# M440 register map
File version: 0.1
Registers are 32-bit, read-write, reset 0x0 unless marked. A register's access mark holds for its fields unless they carry their own. Offsets are from the block's base; [hi:lo] are bit positions; {n}, {i} and the like mark numbered series.

## TC — 32-bit Timer (TC)
Base 0x440CE000
0x00 EN — TC Enable Register
  [7] TCEN
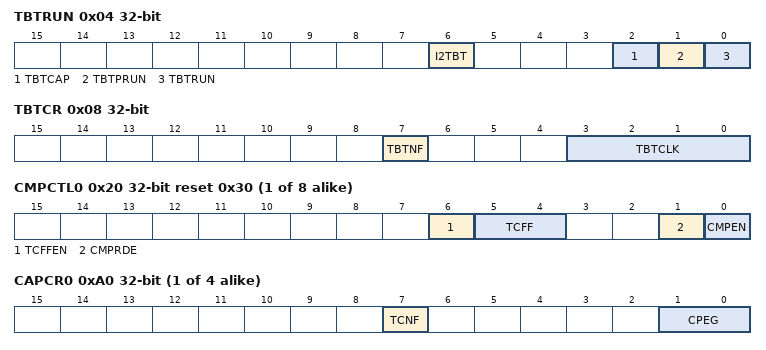
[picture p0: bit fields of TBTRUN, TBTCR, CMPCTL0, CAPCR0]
0x04 TBTRUN — TC RUN Register
  [6] I2TBT, [2] TBTCAP, [1] TBTPRUN, [0] TBTRUN
0x08 TBTCR — TC Control Register
  [7] TBTNF, [3:0] TBTCLK
0x0C TBTCP ro — TC TBT Capture Register
  [31:0] CAP
0x10 TBTRDCP ro — TC TBT Read Capture Register
  [31:0] RDCP
{0x20+0x10*i} CMPCTL{i} reset 0x30 (i=0..7) — TC Compare Control Register{i}
  [6] TCFFEN, [5:4] TCFF, [1] CMPRDE, [0] CMPEN
{0x24+0x10*i} CMP{i} (i=0..7) — TC Compare Register{i}
  [31:0] CMP
{0xA0+0x10*i} CAPCR{i} (i=0..3) — TC Capture Control Register{i}
  [7] TCNF, [1:0] CPEG
{0xA4+0x10*i} CAP{i} ro (i=0..3) — TC Capture Register{i}
  [31:0] CAP

## PHC0 — Two-phase Pulse Input Count
Base 0x400CA000
Same registers: PHC1 0x400CA100
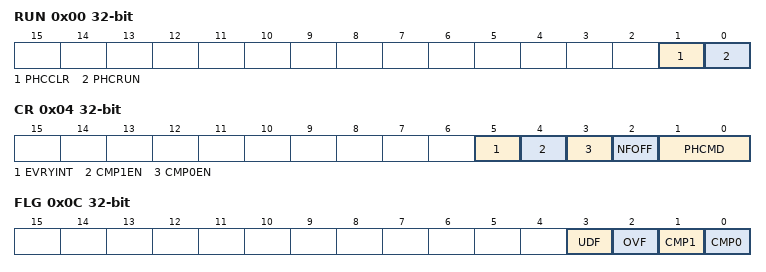
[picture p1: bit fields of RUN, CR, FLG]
0x00 RUN — Two-phase Pulse Input Count Run Register
  [1] PHCCLR, [0] PHCRUN
0x04 CR — Two-phase Pulse Input Count Control Register
  [5] EVRYINT, [4] CMP1EN, [3] CMP0EN, [2] NFOFF, [1:0] PHCMD
0x08 EN — Two-phase Pulse Input Count Timer Enable Register
  [0] PHCEN
0x0C FLG — Two-phase Pulse Input Count Status Register
  [3] UDF, [2] OVF, [1] CMP1, [0] CMP0
0x10 CMP0 — Two-phase Pulse Input Count Compare Register 0
  [15:0] PHCCMP0
0x14 CMP1 — Two-phase Pulse Input Count Compare Register 1
  [15:0] PHCCMP1
0x18 CNT ro reset 0x7FFF — Two-phase Pulse Input Count Counter Read Register
  [15:0] PHCCNT
0x1C DMA — Two-phase Pulse Input Count DMA Enable Register
  [2] PHCDMA2

## RTC — Real Time Clock (RTC)
Base 0x400CC000
0x00 SECR 8-bit (reset mask 0x80) — RTC Second Column Register
  [6:0] SE
0x01 MINR 8-bit (reset mask 0x80) — RTC Minute Column Register
  [6:0] MI
0x02 HOURR 8-bit (reset mask 0xC0) — RTC Hour Column Register
  [5:0] HO
0x04 DAYR 8-bit (reset mask 0xF8) — RTC Day of the Week Column Register
  [2:0] WE
0x05 DATER 8-bit (reset mask 0xC0) — RTC Day Column Register
  [5:0] DA
0x06 MONTHR_A 8-bit (reset mask 0xE0) — RTC Month Column Register
  [4:0] MO
0x06 MONTHR_B 8-bit (reset mask 0xFE) (RTC_MONTHR view) — RTC Month Column Register
  [0] MO0
0x07 YEARR_A 8-bit reset not defined — RTC Year Column Register
  [7:0] YE
0x07 YEARR_B 8-bit (reset mask 0xFC) (RTC_YEARR view) — RTC Year Column Register
  [1:0] LEAP
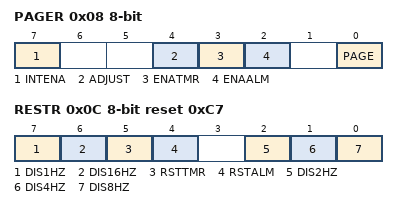
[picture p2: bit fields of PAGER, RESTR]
0x08 PAGER 8-bit (reset mask 0xF3) — RTC PAGE Register
  [7] INTENA, [4] ADJUST, [3] ENATMR, [2] ENAALM, [0] PAGE
0x0C RESTR 8-bit reset 0xC7 — RTC Reset Register
  [7] DIS1HZ, [6] DIS16HZ, [5] RSTTMR, [4] RSTALM, [2] DIS2HZ, [1] DIS4HZ, [0] DIS8HZ

## SBI — Serial Bus Interface (SBI)
Base 0x400E0000
0x00 CR0 — SBI Control Register 0
  [7] SBIEN
0x04 CR1_A reset 0x3 — SBI Control Register 1 (I2C Mode)
  [7:5] BC, [4] ACK, [0] SWRMON ro, [2:0] SCK wo
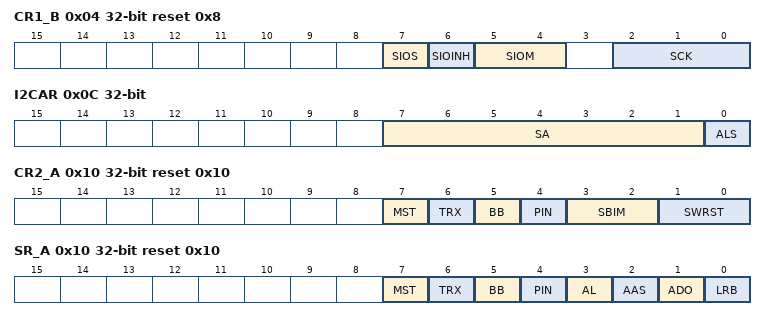
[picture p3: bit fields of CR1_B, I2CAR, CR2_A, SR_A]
0x04 CR1_B reset 0x8 (SBI_CR1 view) — SBI Control Register 1 (SIO Mode)
  [7] SIOS, [6] SIOINH, [5:4] SIOM, [2:0] SCK
0x08 DBR — SBI Data Buffer Register
  [7:0] DB
0x0C I2CAR — SBI I2C Bus Address Register
  [7:1] SA, [0] ALS
0x10 CR2_A wo reset 0x10 — SBI Control Register 2 (I2C Mode)
  [7] MST, [6] TRX, [5] BB, [4] PIN, [3:2] SBIM, [1:0] SWRST
0x10 CR2_B wo reset 0xF3 (SBI_CR2 view) — SBI Control Register 2 (SIO Mode)
  [3:2] SBIM
0x10 SR_A ro reset 0x10 — SBI Status Register (I2C Mode)
  [7] MST, [6] TRX, [5] BB, [4] PIN, [3] AL, [2] AAS, [1] ADO, [0] LRB
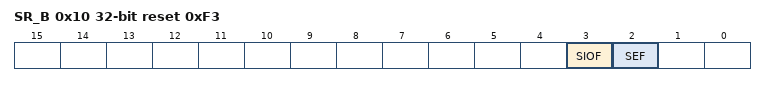
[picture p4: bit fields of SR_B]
0x10 SR_B ro reset 0xF3 (SBI_SR view) — SBI Status Register (SIO Mode)
  [3] SIOF, [2] SEF
0x14 BR0 reset 0xBE — SBI Baud Rate Register 0
  [6] I2SBI

## SC0 — Serial Channel (SC)
Base 0x440E1000
Same registers: SC1 0x440E1100, SC2 0x440E1200
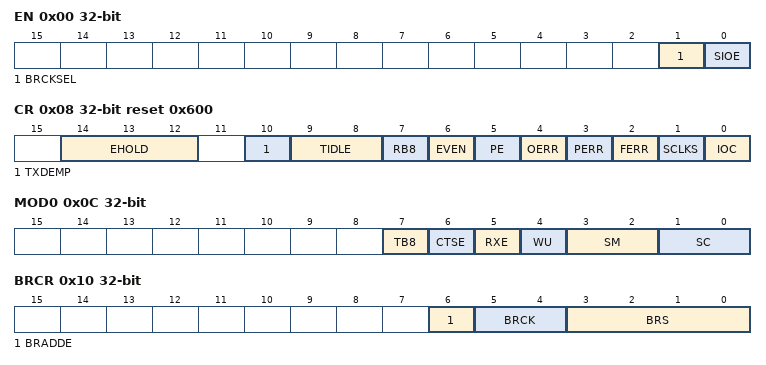
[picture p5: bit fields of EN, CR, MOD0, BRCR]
0x00 EN — SC Enable Register
  [1] BRCKSEL, [0] SIOE
0x04 BUF — SC Buffer Register
  [7:0] TB_RB
0x08 CR reset 0x600 — SC Control Register
  [14:12] EHOLD, [10] TXDEMP, [9:8] TIDLE, [7] RB8 ro, [6] EVEN, [5] PE, [4] OERR ro, [3] PERR ro, [2] FERR ro, [1] SCLKS, [0] IOC
0x0C MOD0 — SC Mode Control Register 0
  [7] TB8, [6] CTSE, [5] RXE, [4] WU, [3:2] SM, [1:0] SC
0x10 BRCR — SC Baud Rate Generator Control Register
  [6] BRADDE, [5:4] BRCK, [3:0] BRS
0x14 BRADD — SC Baud Rate Generator Control Register 2
  [3:0] BRK
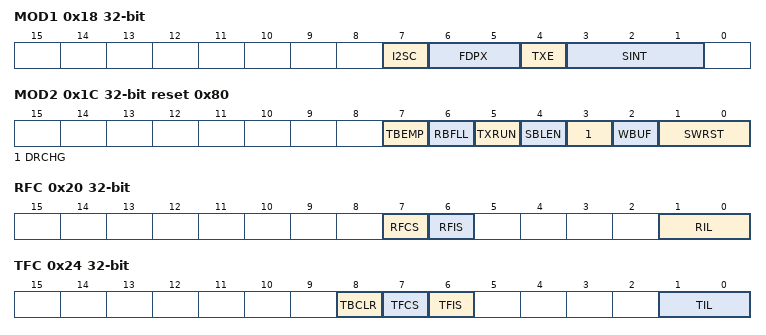
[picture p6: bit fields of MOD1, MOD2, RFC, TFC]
0x18 MOD1 — SC Mode Control Register 1
  [7] I2SC, [6:5] FDPX, [4] TXE, [3:1] SINT
0x1C MOD2 reset 0x80 — SC Mode Control Register 2
  [7] TBEMP ro, [6] RBFLL ro, [5] TXRUN ro, [4] SBLEN, [3] DRCHG, [2] WBUF, [1:0] SWRST
0x20 RFC — SC RX FIFO Configuration Register
  [7] RFCS wo, [6] RFIS, [1:0] RIL
0x24 TFC — SC TX FIFO Configuration Register
  [8] TBCLR, [7] TFCS, [6] TFIS, [1:0] TIL
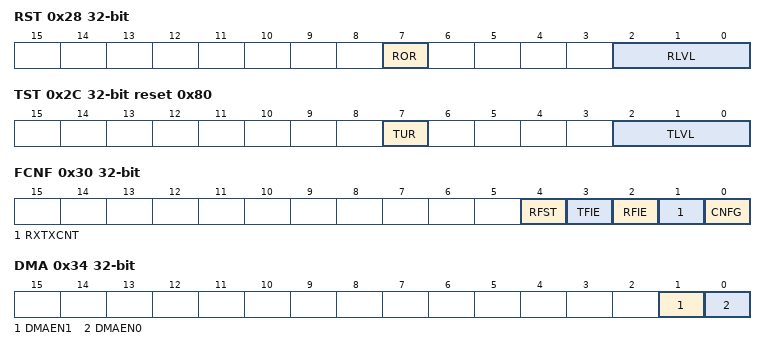
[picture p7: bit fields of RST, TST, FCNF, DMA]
0x28 RST ro — SC RX FIFO Status Register
  [7] ROR, [2:0] RLVL
0x2C TST ro reset 0x80 — SC TX FIFO Status Register
  [7] TUR, [2:0] TLVL
0x30 FCNF — SC FIFO Configuration Register
  [4] RFST, [3] TFIE, [2] RFIE, [1] RXTXCNT, [0] CNFG
0x34 DMA — SC DMA Enable Register
  [1] DMAEN1, [0] DMAEN0

## SC3 — Serial Channel (SC)
Base 0x440E1300
Same registers: SC4 0x440E1400, SC5 0x440E1500
Registers as SC0; these are added or differ:
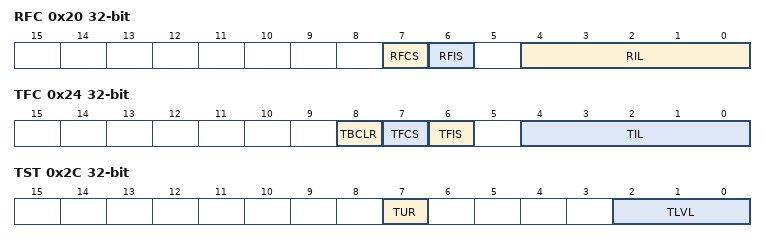
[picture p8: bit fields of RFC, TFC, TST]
0x20 RFC — SC RX FIFO Configuration Register
  [7] RFCS wo, [6] RFIS, [4:0] RIL
0x24 TFC — SC TX FIFO Configuration Register
  [8] TBCLR, [7] TFCS, [6] TFIS, [4:0] TIL
0x2C TST ro — SC TX FIFO Status Register
  [7] TUR, [2:0] TLVL
